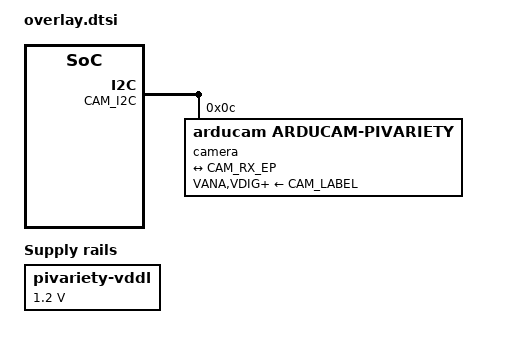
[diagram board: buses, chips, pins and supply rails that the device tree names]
// SPDX-License-Identifier: GPL-2.0
/*
 * Sony IMX230 on an Arducam Pivariety adapter. Same node as the kernel's
 * k3-am67a-t3-gem-o1-csi0-arducam-pivariety.dtso, written against the port
 * macros so it also works on CSI1.
 */

#define CAM_DATA_LANES	1 2
#define CAM_CLOCK_NONCONTINUOUS

/*
 * The driver requires a 24 MHz xclk and the VANA, VDIG and VDDL supplies.
 * The adapter powers itself, so the regulators are placeholders.
 */
&{/} {
	CAM_LABEL(pivariety_xclk): CAM_LABEL(pivariety_xclk) {
		compatible = "fixed-clock";
		#clock-cells = <0>;
		clock-frequency = <24000000>;
	};

	CAM_LABEL(pivariety_vana): CAM_LABEL(pivariety_vana) {
		compatible = "regulator-fixed";
		regulator-name = "pivariety-vana";
		regulator-min-microvolt = <2800000>;
		regulator-max-microvolt = <2800000>;
		regulator-always-on;
		regulator-boot-on;
	};

	CAM_LABEL(pivariety_vdig): CAM_LABEL(pivariety_vdig) {
		compatible = "regulator-fixed";
		regulator-name = "pivariety-vdig";
		regulator-min-microvolt = <1800000>;
		regulator-max-microvolt = <1800000>;
		regulator-always-on;
		regulator-boot-on;
	};

	CAM_LABEL(pivariety_vddl): CAM_LABEL(pivariety_vddl) {
		compatible = "regulator-fixed";
		regulator-name = "pivariety-vddl";
		regulator-min-microvolt = <1200000>;
		regulator-max-microvolt = <1200000>;
		regulator-always-on;
		regulator-boot-on;
	};
};

&CAM_I2C {
	CAM_LABEL(pivariety): camera@c {
		compatible = "arducam,arducam-pivariety";
		reg = <0x0c>;

		clocks = <&CAM_LABEL(pivariety_xclk)>;
		clock-names = "xclk";

		VANA-supply = <&CAM_LABEL(pivariety_vana)>;
		VDIG-supply = <&CAM_LABEL(pivariety_vdig)>;
		VDDL-supply = <&CAM_LABEL(pivariety_vddl)>;

		rotation = <0>;
		orientation = <2>;

		port {
			CAM_SENSOR_EP: endpoint {
				remote-endpoint = <&CAM_RX_EP>;
				link-frequencies = /bits/ 64 <493500000>;
				clock-lanes = <0>;
				data-lanes = <CAM_DATA_LANES>;
				clock-noncontinuous;
			};
		};
	};
};
